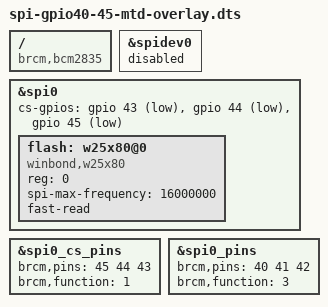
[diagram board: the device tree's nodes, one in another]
/*
 * Boot EEPROM overlay [MTD access]
 */

/dts-v1/;
/plugin/;

/ {
	compatible = "brcm,bcm2835";

	fragment@0 {
        	target = <&spidev0>;
		__overlay__ {
			status = "disabled"; // Disable to avoid conflict
        	};
	};

	fragment@1 {
		target = <&spi0>;
		__overlay__ {
			cs-gpios = <&gpio 43 1>, <&gpio 44 1>, <&gpio 45 1>;
			status = "okay";
			#address-cells = <1>;
			#size-cells = <0>;
			flash: w25x80@0 {
				#address-cells = <1>;
				#size-cells = <1>;
				compatible = "winbond,w25x80", "jedec,spi-nor";
				reg = <0>;
                		spi-max-frequency = <16000000>; // got this value from rpi-eprom-update script
				fast-read; // According to datasheet, current flash supports fast-read
			};
		};
	};

	fragment@2 {
		target = <&spi0_cs_pins>;
		__overlay__ {
			brcm,pins = <45 44 43>;
			brcm,function = <1>; /* output */
			status = "okay";
		};
	};

	fragment@3 {
		target = <&spi0_pins>;
		__overlay__ {
			brcm,pins = <40 41 42>;
			brcm,function = <3>; /* alt4 */
			status = "okay";
		};
	};
};
